# RE01_256KB register map
Vendor: Renesas Electronics Corporation; Series: RE01; File version: 1.00.01
CPU: CM0PLUS r0p1, little endian, MPU, no FPU, VTOR, 2 interrupt priority bits, 32 interrupts
Registers are 8-bit, read-write, reset 0x0 unless marked. A register's access mark holds for its fields unless they carry their own. Offsets are from the block's base; [hi:lo] are bit positions; {n}, {i} and the like mark numbered series.

## TSN — Temperature Sensor
Base 0x4005D000
0x00 TSCR — Temperature Sensor Control Register
  [7] TSEN — Temperature Sensor Enable
    0=Stop the temperature sensor; 1=Start the temperature sensor

## MLCD — MIP LCD Controller
Base 0x40070200
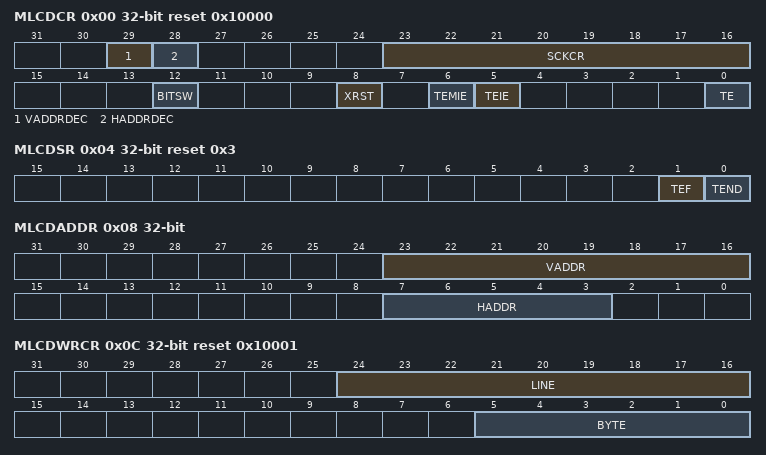
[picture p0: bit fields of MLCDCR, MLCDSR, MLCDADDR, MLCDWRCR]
0x00 MLCDCR 32-bit reset 0x10000 — MLCD Control Register
  [29] VADDRDEC — Vertical Address Control
    0=The address is incremented; 1=The address is decremented
  [28] HADDRDEC — Horizontal Address Control
    0=The address is incremented; 1=The address is decremented
  [23:16] SCKCR — Transmit Clock Control
  [12] BITSW — Endian Conversion
    0=MSB first; 1=LSB first
  [8] XRST — Liquid Crystal Display
    0=Disable MIP LCD panel display; 1=Enable MIP LCD panel display
  [6] TEMIE — Data Register Empty Interrupt Enable
    0=Disable MLCD_TEMI interrupt requests; 1=Enable MLCD_TEMI interrupt requests
  [5] TEIE — Transmit End Interrupt Enable
    0=Disable MLCD_TEI interrupt requests; 1=Enable MLCD_TEI interrupt requests
  [0] TE — MLCD Transmit Enable
    0=Disable data transmission; 1=Enable data transmission
0x04 MLCDSR 32-bit ro reset 0x3 — MLCD Status Register
  [1] TEF — Empty Flag
    0=There is data to be transmitted; 1=Data has been transmitted (the MLCD drawing data setting register is empty)
  [0] TEND — Transmission Flag
    0=Data is being transmitted; 1=Data has been transmitted (transmission stopped)
0x08 MLCDADDR 32-bit — MLCD Address Setting Register
  [23:16] VADDR — Vertical Address Setting
  [7:3] HADDR — Horizontal Address Setting
0x0C MLCDWRCR 32-bit reset 0x10001 — MLCD Transmit Data Size Setting Register
  [24:16] LINE range 0x001..0x100 — Vertical Size Setting
  [5:0] BYTE range 0x01..0x20 — Horizontal Size Setting
0x10 MLCDSEND 32-bit wo — MLCD Same Image Transmit Register
  [0] EN — Same Image Transmit Setting
    0=Disable the same image transmit function; 1=Enable the same image transmit function
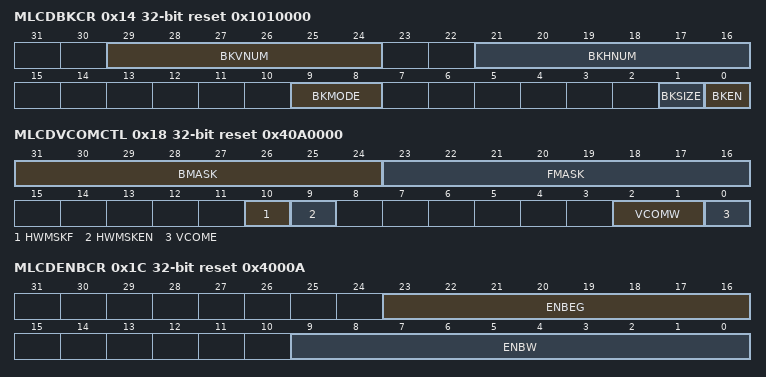
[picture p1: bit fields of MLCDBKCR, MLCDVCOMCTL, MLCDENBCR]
0x14 MLCDBKCR 32-bit reset 0x1010000 — MLCD Block Transfer Setting Register
  [29:24] BKVNUM range 0x01..0x20 — Vertical Transfer Count Setting
  [21:16] BKHNUM range 0x01..0x20 — Horizontal Transfer Count Setting
  [9:8] BKMODE — Block Transfer Mode Setting
    {v}=Transfer mode {v+1} (v=0..3)
  [1] BKSIZE — Block Transfer Size
    0=16 x 16 bit; 1=8 x 8 bit
  [0] BKEN — Block Transfer Enable
    0=Disable block transfer; 1=Enable block transfer
0x18 MLCDVCOMCTL 32-bit reset 0x40A0000 — MLCD VCOM Control Register
  [31:24] BMASK range 0x08..0xFF — VCOM Hardware Mask Range Bits After Data Transmission
  [23:16] FMASK range 0x03..0xFF — VCOM Hardware Mask Range Bits Before Data Transmission
  [10] HWMSKF ro — HW Mask
    0=HW mask is stopped; 1=HW mask is in proceed
  [9] HWMSKEN — HW VCOM Mask
    0=Mask function in transmission disabled; 1=Mask function in transmission enabled
  [2:1] VCOMW — VCOM Output High-Width Setting
    0=1000 ms; 1=500 ms; 2=2000 ms; 3=5000 ms
  [0] VCOME — VCOM Output Enable
    0=Disable MLCD_VCOM output; 1=Enable MLCD_VCOM output
0x1C MLCDENBCR 32-bit reset 0x4000A — MLCD Enable Signal Control Register
  [23:16] ENBEG — Timing Setting
  [9:0] ENBW — High-Width Setting
{0x20+4i} DATA_W{i} (i=0..7) 32-bit — MLCD Drawing Word Data Setting Register
{0x20+2i} DATA_HW{i} (i=0..15) 16-bit — MLCD Drawing Halfword Data Setting Register
{0x20+i} DATA{i} (i=0..31) — MLCD Drawing Byte Data Setting Register

## IRDA — IrDA Interface
Base 0x40070F00
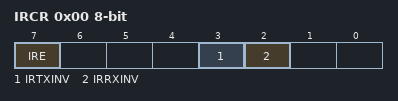
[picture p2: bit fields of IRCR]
0x00 IRCR — IrDA Control Register
  [7] IRE — IrDA Enable
    0=Use serial input/output pins for normal serial communication; 1=Use serial input/output pins for IrDA data communication
  [3] IRTXINV — IRTXD Polarity Switching
    0=Output transmitted data to IRTXD pin as is; 1=Output transmitted data to IRTXD pin after the polarity is inverted
  [2] IRRXINV — IRRXD Polarity Switching
    0=Use input from IRRXD pin as received data as is; 1=Use input from IRRXD pin as received data after the polarity is inverted
